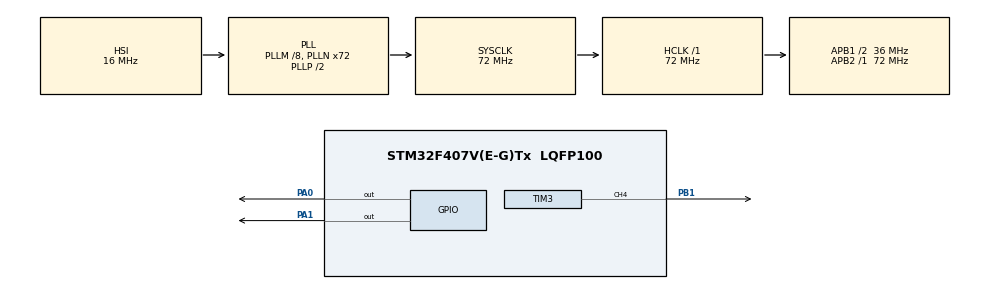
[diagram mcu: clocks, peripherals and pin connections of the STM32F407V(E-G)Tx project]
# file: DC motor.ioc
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Mcu.Family=STM32F4
Mcu.Name=STM32F407V(E-G)Tx
Mcu.Package=LQFP100
NVIC.PriorityGroup=NVIC_PRIORITYGROUP_4
PA0-WKUP.Signal=GPIO_Output
PA1.Signal=GPIO_Output
PB1.Signal=S_TIM3_CH4
PH0-OSC_IN.Mode=HSE-External-Oscillator
PH0-OSC_IN.Signal=RCC_OSC_IN
PH1-OSC_OUT.Mode=HSE-External-Oscillator
PH1-OSC_OUT.Signal=RCC_OSC_OUT
ProjectManager.HeapSize=0x200
ProjectManager.StackSize=0x400
ProjectManager.TargetToolchain=STM32CubeIDE
RCC.48MHZClocksFreq_Value=36000000
RCC.AHBFreq_Value=72000000
RCC.APB1CLKDivider=RCC_HCLK_DIV2
RCC.APB1Freq_Value=36000000
RCC.APB1TimFreq_Value=72000000
RCC.APB2Freq_Value=72000000
RCC.APB2TimFreq_Value=72000000
RCC.CortexFreq_Value=72000000
RCC.HCLKFreq_Value=72000000
RCC.HSE_VALUE=25000000
RCC.HSI_VALUE=16000000
RCC.LSE_VALUE=32768
RCC.PLLM=25
RCC.PLLN=144
RCC.PLLSourceVirtual=RCC_PLLSOURCE_HSE
RCC.SYSCLKFreq_VALUE=72000000
RCC.SYSCLKSource=RCC_SYSCLKSOURCE_PLLCLK
RCC.VCOOutputFreq_Value=144000000
SH.S_TIM3_CH4.0=TIM3_CH4,PWM Generation4 CH4
TIM3.Channel-PWM\ Generation4\ CH4=TIM_CHANNEL_4
TIM3.Period=1000
TIM3.Prescaler=19
TIM3.Pulse-PWM\ Generation4\ CH4=500
VP_TIM3_VS_ClockSourceINT.Mode=Internal
board=custom

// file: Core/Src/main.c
/* USER CODE BEGIN Header */
/**
  ******************************************************************************
  * @file           : main.c
  * @brief          : Main program body
  ******************************************************************************
  * @attention
  *
  * Copyright (c) 2024 STMicroelectronics.
  * All rights reserved.
  *
  * This software is licensed under terms that can be found in the LICENSE file
  * in the root directory of this software component.
  * If no LICENSE file comes with this software, it is provided AS-IS.
  *
  ******************************************************************************
  */
/* USER CODE END Header */
#include "main.h"
#include "stm32f4xx_it.h"

#define A0_Pin GPIO_PIN_0
#define A0_GPIO_Port GPIOA
#define A1_Pin GPIO_PIN_1
#define A1_GPIO_Port GPIOA

TIM_HandleTypeDef htim3;

void SystemClock_Config(void);
static void MX_GPIO_Init(void);
static void MX_TIM3_Init(void);

int main(void)
{

  /* MCU Configuration--------------------------------------------------------*/

  /* Reset of all peripherals, Initializes the Flash interface and the Systick. */
  HAL_Init();

  /* Configure the system clock */
  SystemClock_Config();

  /* Initialize all configured peripherals */
  MX_GPIO_Init();
  MX_TIM3_Init();
  /* USER CODE BEGIN 2 */

  // HAL_GPIO_WritePin(GPIOA,A0_Pin,GPIO_PIN_SET);   // Start motor clock wise rotation
 // HAL_GPIO_WritePin(GPIOA,A1_Pin,GPIO_PIN_RESET);     //rotate motor anti clockwise rotation

  	//HAL_TIM_Base_Start(&htim3);               //Initialize stm32 timer 3
  	//HAL_TIM_PWM_Start(&htim3,TIM_CHANNEL_4);  //PB1 Start pwm for motor at 100% duty cycle
  /* USER CODE END 2 */

  /* Infinite loop */
  while (1)
  {
	  // Set A0 high (clockwise) and A1 low
	      HAL_GPIO_WritePin(GPIOA, GPIO_PIN_0, GPIO_PIN_SET);
	      HAL_GPIO_WritePin(GPIOA, GPIO_PIN_1, GPIO_PIN_RESET);

	      // Set PWM duty cycle to 25% (adjust as necessary)
	      __HAL_TIM_SET_COMPARE(&htim3, TIM_CHANNEL_4, 500); // 25% of 1000 (period set in MX_TIM3_Init)

	      // Delay for motor to run (adjust as necessary)
	      HAL_Delay(3000);

	      // Toggle A0 and A1 for anti-clockwise rotation
	     // HAL_GPIO_WritePin(GPIOA, GPIO_PIN_0, GPIO_PIN_RESET);
	     // HAL_GPIO_WritePin(GPIOA, GPIO_PIN_1, GPIO_PIN_SET);
	     // __HAL_TIM_SET_COMPARE(&htim3, TIM_CHANNEL_4, 100);
	      // Delay for motor to stop and change direction (adjust as necessary)
	     // HAL_Delay(1000);
	      __HAL_TIM_SET_COMPARE(&htim3, TIM_CHANNEL_4, 0);
	      HAL_Delay(1000);

	      // Rotate motor anti-clockwise (A0 low, A1 high)
	          HAL_GPIO_WritePin(GPIOA, GPIO_PIN_0, GPIO_PIN_RESET);
	          HAL_GPIO_WritePin(GPIOA, GPIO_PIN_1, GPIO_PIN_SET);

	          // Set PWM duty cycle (if necessary)
	              __HAL_TIM_SET_COMPARE(&htim3, TIM_CHANNEL_4, 100); // Example: 10% duty cycle

	              HAL_Delay(3000);  // Delay for motor to run in this direction

	              // Stop motor
	              __HAL_TIM_SET_COMPARE(&htim3, TIM_CHANNEL_4, 0);

	              HAL_Delay(1000);  // Delay before changing direction
  }
}

void SystemClock_Config(void)
{
  RCC_OscInitTypeDef RCC_OscInitStruct = {0};
  RCC_ClkInitTypeDef RCC_ClkInitStruct = {0};

  /** Configure the main internal regulator output voltage
  */
  __HAL_RCC_PWR_CLK_ENABLE();
  __HAL_PWR_VOLTAGESCALING_CONFIG(PWR_REGULATOR_VOLTAGE_SCALE1);

  /** Initializes the RCC Oscillators according to the specified parameters
  * in the RCC_OscInitTypeDef structure.
  */
  RCC_OscInitStruct.OscillatorType = RCC_OSCILLATORTYPE_HSI;
  RCC_OscInitStruct.HSIState = RCC_HSI_ON;
  RCC_OscInitStruct.HSICalibrationValue = RCC_HSICALIBRATION_DEFAULT;
  RCC_OscInitStruct.PLL.PLLState = RCC_PLL_ON;
  RCC_OscInitStruct.PLL.PLLSource = RCC_PLLSOURCE_HSI;
  RCC_OscInitStruct.PLL.PLLM = 8;
  RCC_OscInitStruct.PLL.PLLN = 72;
  RCC_OscInitStruct.PLL.PLLP = RCC_PLLP_DIV2;
  RCC_OscInitStruct.PLL.PLLQ = 4;
  if (HAL_RCC_OscConfig(&RCC_OscInitStruct) != HAL_OK)
  {
    Error_Handler();
  }

  /** Initializes the CPU, AHB and APB buses clocks
  */
  RCC_ClkInitStruct.ClockType = RCC_CLOCKTYPE_HCLK|RCC_CLOCKTYPE_SYSCLK
                              |RCC_CLOCKTYPE_PCLK1|RCC_CLOCKTYPE_PCLK2;
  RCC_ClkInitStruct.SYSCLKSource = RCC_SYSCLKSOURCE_PLLCLK;
  RCC_ClkInitStruct.AHBCLKDivider = RCC_SYSCLK_DIV1;
  RCC_ClkInitStruct.APB1CLKDivider = RCC_HCLK_DIV2;
  RCC_ClkInitStruct.APB2CLKDivider = RCC_HCLK_DIV1;

  if (HAL_RCC_ClockConfig(&RCC_ClkInitStruct, FLASH_LATENCY_2) != HAL_OK)
  {
    Error_Handler();
  }
}

static void MX_TIM3_Init(void)
{

  TIM_ClockConfigTypeDef sClockSourceConfig = {0};
  TIM_MasterConfigTypeDef sMasterConfig = {0};
  TIM_OC_InitTypeDef sConfigOC = {0};

  htim3.Instance = TIM3;
  htim3.Init.Prescaler = 19;
  htim3.Init.CounterMode = TIM_COUNTERMODE_UP;
  htim3.Init.Period = 1000;
  htim3.Init.ClockDivision = TIM_CLOCKDIVISION_DIV1;
  htim3.Init.AutoReloadPreload = TIM_AUTORELOAD_PRELOAD_DISABLE;
  if (HAL_TIM_Base_Init(&htim3) != HAL_OK)
  {
    Error_Handler();
  }
  sClockSourceConfig.ClockSource = TIM_CLOCKSOURCE_INTERNAL;
  if (HAL_TIM_ConfigClockSource(&htim3, &sClockSourceConfig) != HAL_OK)
  {
    Error_Handler();
  }
  if (HAL_TIM_PWM_Init(&htim3) != HAL_OK)
  {
    Error_Handler();
  }
  sMasterConfig.MasterOutputTrigger = TIM_TRGO_RESET;
  sMasterConfig.MasterSlaveMode = TIM_MASTERSLAVEMODE_DISABLE;
  if (HAL_TIMEx_MasterConfigSynchronization(&htim3, &sMasterConfig) != HAL_OK)
  {
    Error_Handler();
  }
  sConfigOC.OCMode = TIM_OCMODE_PWM1;
  sConfigOC.Pulse = 500;
  sConfigOC.OCPolarity = TIM_OCPOLARITY_HIGH;
  sConfigOC.OCFastMode = TIM_OCFAST_DISABLE;
  if (HAL_TIM_PWM_ConfigChannel(&htim3, &sConfigOC, TIM_CHANNEL_4) != HAL_OK)
  {
    Error_Handler();
  }
  HAL_TIM_MspPostInit(&htim3);

}

static void MX_GPIO_Init(void)
{
  GPIO_InitTypeDef GPIO_InitStruct = {0};

  /* GPIO Ports Clock Enable */
  __HAL_RCC_GPIOH_CLK_ENABLE();
  __HAL_RCC_GPIOA_CLK_ENABLE();
  __HAL_RCC_GPIOB_CLK_ENABLE();

  /*Configure GPIO pin Output Level */
  HAL_GPIO_WritePin(GPIOA, GPIO_PIN_0|GPIO_PIN_1, GPIO_PIN_RESET);

  /*Configure GPIO pins : PA0 PA1 */
  GPIO_InitStruct.Pin = GPIO_PIN_0|GPIO_PIN_1;
  GPIO_InitStruct.Mode = GPIO_MODE_OUTPUT_PP;
  GPIO_InitStruct.Pull = GPIO_NOPULL;
  GPIO_InitStruct.Speed = GPIO_SPEED_FREQ_LOW;
  HAL_GPIO_Init(GPIOA, &GPIO_InitStruct);

  // Initial state: A0 high (clockwise), A1 low (default direction)
    HAL_GPIO_WritePin(GPIOA, GPIO_PIN_0, GPIO_PIN_SET);   // A0 high
    HAL_GPIO_WritePin(GPIOA, GPIO_PIN_1, GPIO_PIN_RESET); // A1 low
}

void Error_Handler(void)
{
  __disable_irq();
  while (1)
  {
  }
}
